AUTOSAR XML (schema 4-0-3)
package /ComponentTypes
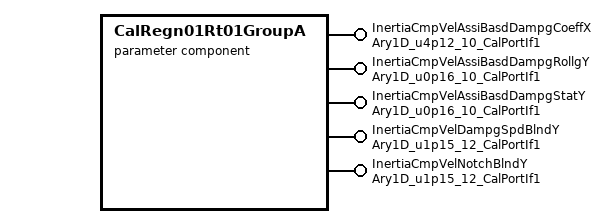
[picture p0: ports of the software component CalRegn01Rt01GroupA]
  parameter sw component type CalRegn01Rt01GroupA
    5 x provide port:
      InertiaCmpVelAssiBasdDampgCoeffX: parameter-provide-com-spec{init-value=[0, 2048, 4096, 6144, 8192, 10240, 12288, 14336, 16384, 18432], parameter=Ary1D}, provided-interface=Ary1D_u4p12_10_CalPortIf1
      InertiaCmpVelAssiBasdDampgRollgY: parameter-provide-com-spec{init-value=10 x 0, parameter=Ary1D}, provided-interface=Ary1D_u0p16_10_CalPortIf1
      InertiaCmpVelAssiBasdDampgStatY: parameter-provide-com-spec{init-value=10 x 0, parameter=Ary1D}, provided-interface=Ary1D_u0p16_10_CalPortIf1
      InertiaCmpVelDampgSpdBlndY: parameter-provide-com-spec{init-value=[32768, 32768, 9830, 6554, 3277, 0, 0, 0, 0, 0, 0, 0], parameter=Ary1D}, provided-interface=Ary1D_u1p15_12_CalPortIf1
      InertiaCmpVelNotchBlndY: parameter-provide-com-spec{init-value=12 x 0, parameter=Ary1D}, provided-interface=Ary1D_u1p15_12_CalPortIf1
